VERSION ""

NS_ :

BS_:

BU_: VCU Orion_2_BMS Client TS_Fan_ECU TS_ECU5 TS_ECU4 TS_ECU3 TS_ECU2 TS_ECU1

BO_ 698 TS_ECU_ChargingStateTrigger: 1 Orion_2_BMS
 SG_ Orion_2_ChargePowerState : 0|1@1+ (1,0) [0|1] ""  TS_ECU5,TS_ECU4,TS_ECU3,TS_ECU2,TS_ECU1
 SG_ Orion_2_ChargeSafetyState : 1|1@1+ (1,0) [0|1] ""  TS_ECU5,TS_ECU4,TS_ECU3,TS_ECU2,TS_ECU1

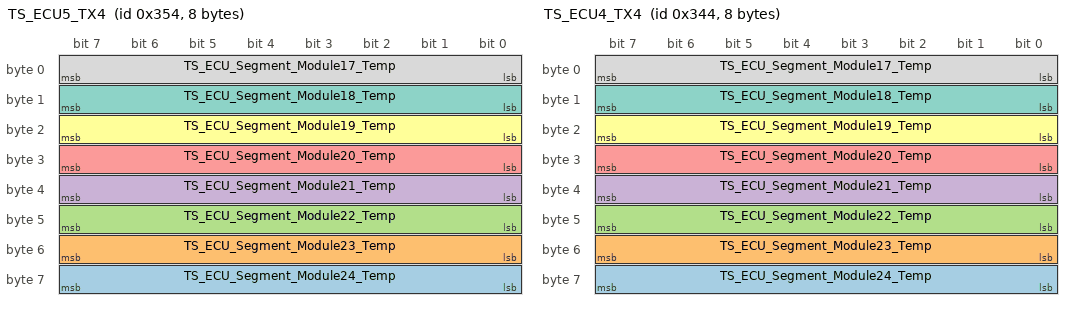
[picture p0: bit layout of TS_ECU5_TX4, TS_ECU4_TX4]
BO_ 852 TS_ECU5_TX4: 8 TS_ECU5
 SG_ TS_ECU_Segment_Module24_Temp : 63|8@0+ (1,-40) [-40|215] " °C"  Client
 SG_ TS_ECU_Segment_Module23_Temp : 48|8@1+ (1,-40) [-40|215] " °C"  Client
 SG_ TS_ECU_Segment_Module22_Temp : 40|8@1+ (1,-40) [-40|215] " °C"  Client
 SG_ TS_ECU_Segment_Module21_Temp : 32|8@1+ (1,-40) [-40|215] " °C"  Client
 SG_ TS_ECU_Segment_Module20_Temp : 24|8@1+ (1,-40) [-40|215] " °C"  Client
 SG_ TS_ECU_Segment_Module19_Temp : 16|8@1+ (1,-40) [-40|215] " °C"  Client
 SG_ TS_ECU_Segment_Module18_Temp : 8|8@1+ (1,-40) [-40|215] " °C"  Client
 SG_ TS_ECU_Segment_Module17_Temp : 0|8@1+ (1,-40) [-40|215] " °C"  Client

BO_ 836 TS_ECU4_TX4: 8 TS_ECU4
 SG_ TS_ECU_Segment_Module24_Temp : 63|8@0+ (1,-40) [-40|215] " °C"  Client
 SG_ TS_ECU_Segment_Module23_Temp : 48|8@1+ (1,-40) [-40|215] " °C"  Client
 SG_ TS_ECU_Segment_Module22_Temp : 40|8@1+ (1,-40) [-40|215] " °C"  Client
 SG_ TS_ECU_Segment_Module21_Temp : 32|8@1+ (1,-40) [-40|215] " °C"  Client
 SG_ TS_ECU_Segment_Module20_Temp : 24|8@1+ (1,-40) [-40|215] " °C"  Client
 SG_ TS_ECU_Segment_Module19_Temp : 16|8@1+ (1,-40) [-40|215] " °C"  Client
 SG_ TS_ECU_Segment_Module18_Temp : 8|8@1+ (1,-40) [-40|215] " °C"  Client
 SG_ TS_ECU_Segment_Module17_Temp : 0|8@1+ (1,-40) [-40|215] " °C"  Client

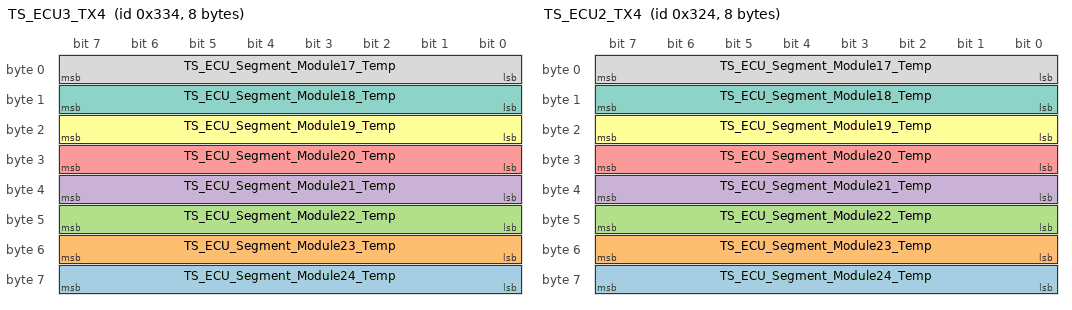
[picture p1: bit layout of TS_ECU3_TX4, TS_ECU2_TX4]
BO_ 820 TS_ECU3_TX4: 8 TS_ECU3
 SG_ TS_ECU_Segment_Module24_Temp : 63|8@0+ (1,-40) [-40|215] " °C"  Client
 SG_ TS_ECU_Segment_Module23_Temp : 48|8@1+ (1,-40) [-40|215] " °C"  Client
 SG_ TS_ECU_Segment_Module22_Temp : 40|8@1+ (1,-40) [-40|215] " °C"  Client
 SG_ TS_ECU_Segment_Module21_Temp : 32|8@1+ (1,-40) [-40|215] " °C"  Client
 SG_ TS_ECU_Segment_Module20_Temp : 24|8@1+ (1,-40) [-40|215] " °C"  Client
 SG_ TS_ECU_Segment_Module19_Temp : 16|8@1+ (1,-40) [-40|215] " °C"  Client
 SG_ TS_ECU_Segment_Module18_Temp : 8|8@1+ (1,-40) [-40|215] " °C"  Client
 SG_ TS_ECU_Segment_Module17_Temp : 0|8@1+ (1,-40) [-40|215] " °C"  Client

BO_ 804 TS_ECU2_TX4: 8 TS_ECU2
 SG_ TS_ECU_Segment_Module24_Temp : 63|8@0+ (1,-40) [-40|215] " °C"  Client
 SG_ TS_ECU_Segment_Module23_Temp : 48|8@1+ (1,-40) [-40|215] " °C"  Client
 SG_ TS_ECU_Segment_Module22_Temp : 40|8@1+ (1,-40) [-40|215] " °C"  Client
 SG_ TS_ECU_Segment_Module21_Temp : 32|8@1+ (1,-40) [-40|215] " °C"  Client
 SG_ TS_ECU_Segment_Module20_Temp : 24|8@1+ (1,-40) [-40|215] " °C"  Client
 SG_ TS_ECU_Segment_Module19_Temp : 16|8@1+ (1,-40) [-40|215] " °C"  Client
 SG_ TS_ECU_Segment_Module18_Temp : 8|8@1+ (1,-40) [-40|215] " °C"  Client
 SG_ TS_ECU_Segment_Module17_Temp : 0|8@1+ (1,-40) [-40|215] " °C"  Client

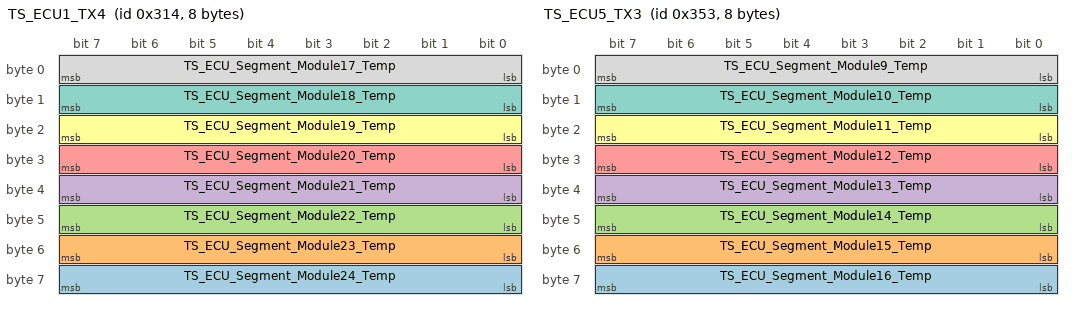
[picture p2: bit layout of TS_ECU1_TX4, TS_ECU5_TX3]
BO_ 788 TS_ECU1_TX4: 8 TS_ECU1
 SG_ TS_ECU_Segment_Module24_Temp : 63|8@0+ (1,-40) [-40|215] " °C"  Client
 SG_ TS_ECU_Segment_Module23_Temp : 48|8@1+ (1,-40) [-40|215] " °C"  Client
 SG_ TS_ECU_Segment_Module22_Temp : 40|8@1+ (1,-40) [-40|215] " °C"  Client
 SG_ TS_ECU_Segment_Module21_Temp : 32|8@1+ (1,-40) [-40|215] " °C"  Client
 SG_ TS_ECU_Segment_Module20_Temp : 24|8@1+ (1,-40) [-40|215] " °C"  Client
 SG_ TS_ECU_Segment_Module19_Temp : 16|8@1+ (1,-40) [-40|215] " °C"  Client
 SG_ TS_ECU_Segment_Module18_Temp : 8|8@1+ (1,-40) [-40|215] " °C"  Client
 SG_ TS_ECU_Segment_Module17_Temp : 0|8@1+ (1,-40) [-40|215] " °C"  Client

BO_ 851 TS_ECU5_TX3: 8 TS_ECU5
 SG_ TS_ECU_Segment_Module16_Temp : 56|8@1+ (1,-40) [-40|215] "°C"  Client
 SG_ TS_ECU_Segment_Module15_Temp : 48|8@1+ (1,-40) [-40|215] "°C"  Client
 SG_ TS_ECU_Segment_Module14_Temp : 40|8@1+ (1,-40) [-40|215] "°C"  Client
 SG_ TS_ECU_Segment_Module13_Temp : 32|8@1+ (1,-40) [-40|215] "°C"  Client
 SG_ TS_ECU_Segment_Module12_Temp : 24|8@1+ (1,-40) [-40|215] "°C"  Client
 SG_ TS_ECU_Segment_Module11_Temp : 16|8@1+ (1,0) [0|255] "°C"  Client
 SG_ TS_ECU_Segment_Module10_Temp : 8|8@1+ (1,-40) [-40|215] "°C"  Client
 SG_ TS_ECU_Segment_Module9_Temp : 0|8@1+ (1,-40) [-40|215] "°C"  Client

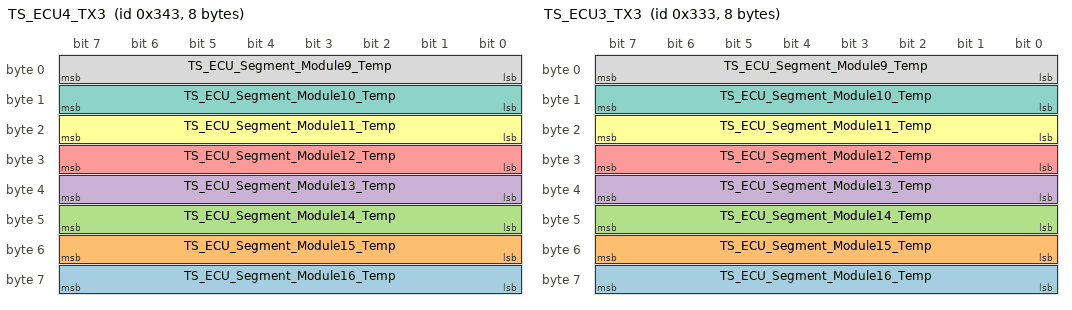
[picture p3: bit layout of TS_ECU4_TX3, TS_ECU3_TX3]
BO_ 835 TS_ECU4_TX3: 8 TS_ECU4
 SG_ TS_ECU_Segment_Module16_Temp : 56|8@1+ (1,-40) [-40|215] "°C"  Client
 SG_ TS_ECU_Segment_Module15_Temp : 48|8@1+ (1,-40) [-40|215] "°C"  Client
 SG_ TS_ECU_Segment_Module14_Temp : 40|8@1+ (1,-40) [-40|215] "°C"  Client
 SG_ TS_ECU_Segment_Module13_Temp : 32|8@1+ (1,-40) [-40|215] "°C"  Client
 SG_ TS_ECU_Segment_Module12_Temp : 24|8@1+ (1,-40) [-40|215] "°C"  Client
 SG_ TS_ECU_Segment_Module11_Temp : 16|8@1+ (1,0) [0|255] "°C"  Client
 SG_ TS_ECU_Segment_Module10_Temp : 8|8@1+ (1,-40) [-40|215] "°C"  Client
 SG_ TS_ECU_Segment_Module9_Temp : 0|8@1+ (1,-40) [-40|215] "°C"  Client

BO_ 819 TS_ECU3_TX3: 8 TS_ECU3
 SG_ TS_ECU_Segment_Module16_Temp : 56|8@1+ (1,-40) [-40|215] "°C"  Client
 SG_ TS_ECU_Segment_Module15_Temp : 48|8@1+ (1,-40) [-40|215] "°C"  Client
 SG_ TS_ECU_Segment_Module14_Temp : 40|8@1+ (1,-40) [-40|215] "°C"  Client
 SG_ TS_ECU_Segment_Module13_Temp : 32|8@1+ (1,-40) [-40|215] "°C"  Client
 SG_ TS_ECU_Segment_Module12_Temp : 24|8@1+ (1,-40) [-40|215] "°C"  Client
 SG_ TS_ECU_Segment_Module11_Temp : 16|8@1+ (1,0) [0|255] "°C"  Client
 SG_ TS_ECU_Segment_Module10_Temp : 8|8@1+ (1,-40) [-40|215] "°C"  Client
 SG_ TS_ECU_Segment_Module9_Temp : 0|8@1+ (1,-40) [-40|215] "°C"  Client

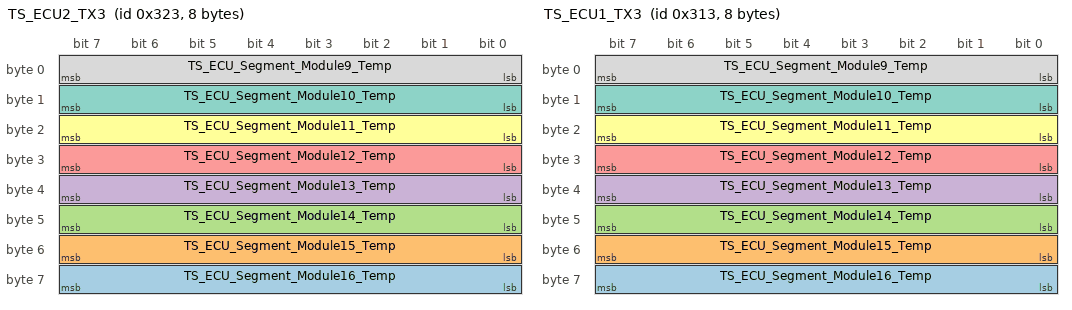
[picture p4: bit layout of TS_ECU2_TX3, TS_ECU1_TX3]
BO_ 803 TS_ECU2_TX3: 8 TS_ECU2
 SG_ TS_ECU_Segment_Module16_Temp : 56|8@1+ (1,-40) [-40|215] "°C"  Client
 SG_ TS_ECU_Segment_Module15_Temp : 48|8@1+ (1,-40) [-40|215] "°C"  Client
 SG_ TS_ECU_Segment_Module14_Temp : 40|8@1+ (1,-40) [-40|215] "°C"  Client
 SG_ TS_ECU_Segment_Module13_Temp : 32|8@1+ (1,-40) [-40|215] "°C"  Client
 SG_ TS_ECU_Segment_Module12_Temp : 24|8@1+ (1,-40) [-40|215] "°C"  Client
 SG_ TS_ECU_Segment_Module11_Temp : 16|8@1+ (1,0) [0|255] "°C"  Client
 SG_ TS_ECU_Segment_Module10_Temp : 8|8@1+ (1,-40) [-40|215] "°C"  Client
 SG_ TS_ECU_Segment_Module9_Temp : 0|8@1+ (1,-40) [-40|215] "°C"  Client

BO_ 787 TS_ECU1_TX3: 8 TS_ECU1
 SG_ TS_ECU_Segment_Module16_Temp : 56|8@1+ (1,-40) [-40|215] "°C"  Client
 SG_ TS_ECU_Segment_Module15_Temp : 48|8@1+ (1,-40) [-40|215] "°C"  Client
 SG_ TS_ECU_Segment_Module14_Temp : 40|8@1+ (1,-40) [-40|215] "°C"  Client
 SG_ TS_ECU_Segment_Module13_Temp : 32|8@1+ (1,-40) [-40|215] "°C"  Client
 SG_ TS_ECU_Segment_Module12_Temp : 24|8@1+ (1,-40) [-40|215] "°C"  Client
 SG_ TS_ECU_Segment_Module11_Temp : 16|8@1+ (1,0) [0|255] "°C"  Client
 SG_ TS_ECU_Segment_Module10_Temp : 8|8@1+ (1,-40) [-40|215] "°C"  Client
 SG_ TS_ECU_Segment_Module9_Temp : 0|8@1+ (1,-40) [-40|215] "°C"  Client

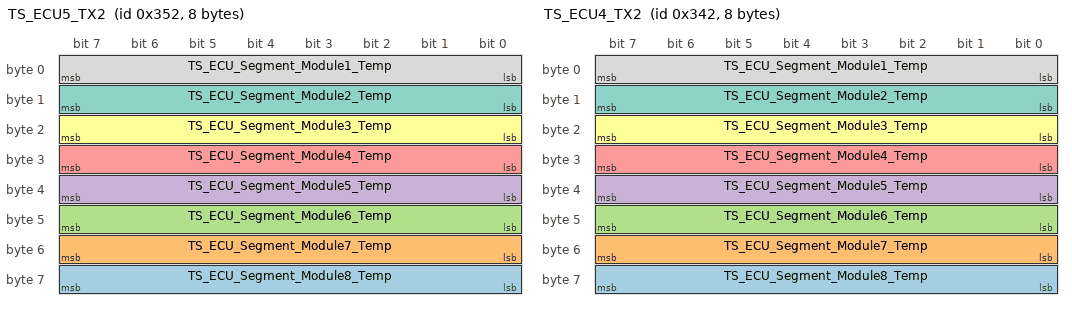
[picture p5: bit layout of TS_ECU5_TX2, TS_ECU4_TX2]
BO_ 850 TS_ECU5_TX2: 8 TS_ECU5
 SG_ TS_ECU_Segment_Module8_Temp : 56|8@1+ (1,-40) [-40|215] "°C"  Client
 SG_ TS_ECU_Segment_Module7_Temp : 48|8@1+ (1,-40) [-40|215] "°C"  Client
 SG_ TS_ECU_Segment_Module6_Temp : 40|8@1+ (1,-40) [-40|215] "°C"  Client
 SG_ TS_ECU_Segment_Module5_Temp : 32|8@1+ (1,-40) [-40|215] "°C"  Client
 SG_ TS_ECU_Segment_Module4_Temp : 24|8@1+ (1,-40) [-40|215] "°C"  Client
 SG_ TS_ECU_Segment_Module3_Temp : 16|8@1+ (1,-40) [-40|215] "°C"  Client
 SG_ TS_ECU_Segment_Module2_Temp : 8|8@1+ (1,-40) [-40|215] "°C"  Client
 SG_ TS_ECU_Segment_Module1_Temp : 0|8@1+ (1,-40) [-40|215] "°C"  Client

BO_ 834 TS_ECU4_TX2: 8 TS_ECU4
 SG_ TS_ECU_Segment_Module8_Temp : 56|8@1+ (1,-40) [-40|215] "°C"  Client
 SG_ TS_ECU_Segment_Module7_Temp : 48|8@1+ (1,-40) [-40|215] "°C"  Client
 SG_ TS_ECU_Segment_Module6_Temp : 40|8@1+ (1,-40) [-40|215] "°C"  Client
 SG_ TS_ECU_Segment_Module5_Temp : 32|8@1+ (1,-40) [-40|215] "°C"  Client
 SG_ TS_ECU_Segment_Module4_Temp : 24|8@1+ (1,-40) [-40|215] "°C"  Client
 SG_ TS_ECU_Segment_Module3_Temp : 16|8@1+ (1,-40) [-40|215] "°C"  Client
 SG_ TS_ECU_Segment_Module2_Temp : 8|8@1+ (1,-40) [-40|215] "°C"  Client
 SG_ TS_ECU_Segment_Module1_Temp : 0|8@1+ (1,-40) [-40|215] "°C"  Client

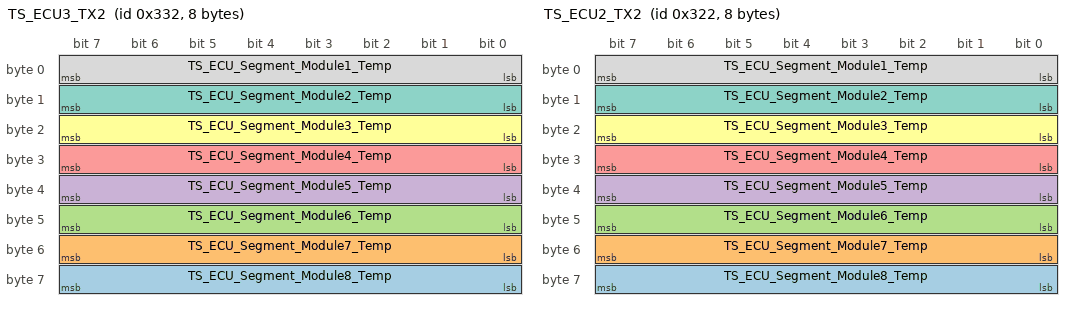
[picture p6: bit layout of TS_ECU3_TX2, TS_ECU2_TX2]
BO_ 818 TS_ECU3_TX2: 8 TS_ECU3
 SG_ TS_ECU_Segment_Module8_Temp : 56|8@1+ (1,-40) [-40|215] "°C"  Client
 SG_ TS_ECU_Segment_Module7_Temp : 48|8@1+ (1,-40) [-40|215] "°C"  Client
 SG_ TS_ECU_Segment_Module6_Temp : 40|8@1+ (1,-40) [-40|215] "°C"  Client
 SG_ TS_ECU_Segment_Module5_Temp : 32|8@1+ (1,-40) [-40|215] "°C"  Client
 SG_ TS_ECU_Segment_Module4_Temp : 24|8@1+ (1,-40) [-40|215] "°C"  Client
 SG_ TS_ECU_Segment_Module3_Temp : 16|8@1+ (1,-40) [-40|215] "°C"  Client
 SG_ TS_ECU_Segment_Module2_Temp : 8|8@1+ (1,-40) [-40|215] "°C"  Client
 SG_ TS_ECU_Segment_Module1_Temp : 0|8@1+ (1,-40) [-40|215] "°C"  Client

BO_ 802 TS_ECU2_TX2: 8 TS_ECU2
 SG_ TS_ECU_Segment_Module8_Temp : 56|8@1+ (1,-40) [-40|215] "°C"  Client
 SG_ TS_ECU_Segment_Module7_Temp : 48|8@1+ (1,-40) [-40|215] "°C"  Client
 SG_ TS_ECU_Segment_Module6_Temp : 40|8@1+ (1,-40) [-40|215] "°C"  Client
 SG_ TS_ECU_Segment_Module5_Temp : 32|8@1+ (1,-40) [-40|215] "°C"  Client
 SG_ TS_ECU_Segment_Module4_Temp : 24|8@1+ (1,-40) [-40|215] "°C"  Client
 SG_ TS_ECU_Segment_Module3_Temp : 16|8@1+ (1,-40) [-40|215] "°C"  Client
 SG_ TS_ECU_Segment_Module2_Temp : 8|8@1+ (1,-40) [-40|215] "°C"  Client
 SG_ TS_ECU_Segment_Module1_Temp : 0|8@1+ (1,-40) [-40|215] "°C"  Client

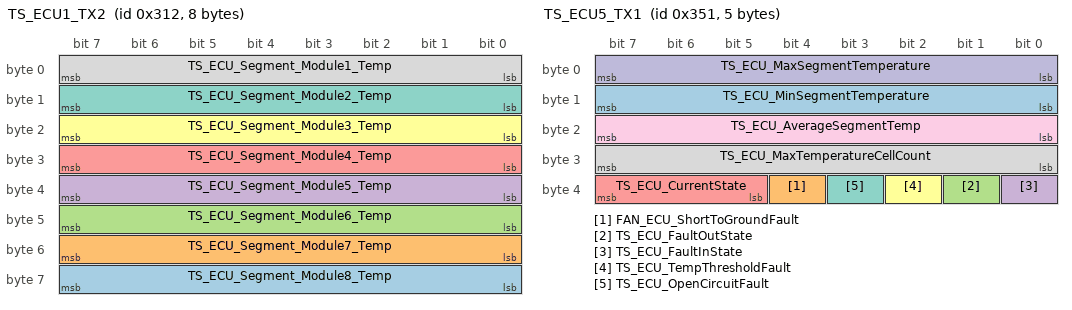
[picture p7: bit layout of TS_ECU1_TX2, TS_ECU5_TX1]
BO_ 786 TS_ECU1_TX2: 8 TS_ECU1
 SG_ TS_ECU_Segment_Module8_Temp : 56|8@1+ (1,-40) [-40|215] "°C"  Client
 SG_ TS_ECU_Segment_Module7_Temp : 48|8@1+ (1,-40) [-40|215] "°C"  Client
 SG_ TS_ECU_Segment_Module6_Temp : 40|8@1+ (1,-40) [-40|215] "°C"  Client
 SG_ TS_ECU_Segment_Module5_Temp : 32|8@1+ (1,-40) [-40|215] "°C"  Client
 SG_ TS_ECU_Segment_Module4_Temp : 24|8@1+ (1,-40) [-40|215] "°C"  Client
 SG_ TS_ECU_Segment_Module3_Temp : 16|8@1+ (1,-40) [-40|215] "°C"  Client
 SG_ TS_ECU_Segment_Module2_Temp : 8|8@1+ (1,-40) [-40|215] "°C"  Client
 SG_ TS_ECU_Segment_Module1_Temp : 0|8@1+ (1,-40) [-40|215] "°C"  Client

BO_ 770 TS_ECU_SYNC_RX2: 1 Client
 SG_ TS_ECU_SYNC_COUNTER : 0|8@1+ (1,0) [0|255] ""  TS_ECU1,TS_ECU5,TS_ECU4,TS_ECU3,TS_ECU2

BO_ 769 TS_ECU_SYNC_RX1: 1 TS_Fan_ECU
 SG_ TS_ECU_SYNC_COUNTER : 0|8@1+ (1,0) [0|255] ""  TS_ECU1,TS_ECU5,TS_ECU4,TS_ECU3,TS_ECU2

BO_ 849 TS_ECU5_TX1: 5 TS_ECU5
 SG_ TS_ECU_MinSegmentTemperature : 8|8@1+ (1,-40) [-40|215] "" Vector__XXX
 SG_ FAN_ECU_ShortToGroundFault : 36|1@1+ (1,0) [0|1] "" Vector__XXX
 SG_ TS_ECU_FaultOutState : 33|1@1+ (1,0) [0|1] "" Vector__XXX
 SG_ TS_ECU_FaultInState : 32|1@1+ (1,0) [0|1] "" Vector__XXX
 SG_ TS_ECU_CurrentState : 37|3@1+ (1,0) [0|1] "" Vector__XXX
 SG_ TS_ECU_TempThresholdFault : 34|1@1+ (1,0) [0|1] ""  VCU,TS_Fan_ECU,Client
 SG_ TS_ECU_OpenCircuitFault : 35|1@1+ (1,0) [0|1] ""  VCU,TS_Fan_ECU,Client
 SG_ TS_ECU_MaxTemperatureCellCount : 24|8@1+ (1,0) [0|63] ""  VCU,TS_Fan_ECU,Client
 SG_ TS_ECU_AverageSegmentTemp : 16|8@1+ (1,-40) [-40|215] " °C"  VCU,TS_Fan_ECU,Client
 SG_ TS_ECU_MaxSegmentTemperature : 0|8@1+ (1,-40) [-40|215] " °C"  VCU,TS_Fan_ECU,Client

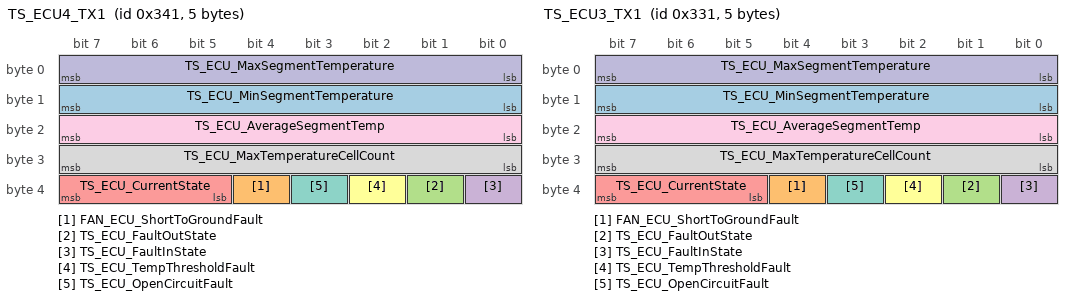
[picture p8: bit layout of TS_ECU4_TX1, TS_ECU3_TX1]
BO_ 833 TS_ECU4_TX1: 5 TS_ECU4
 SG_ TS_ECU_MinSegmentTemperature : 8|8@1+ (1,-40) [-40|215] "" Vector__XXX
 SG_ FAN_ECU_ShortToGroundFault : 36|1@1+ (1,0) [0|1] "" Vector__XXX
 SG_ TS_ECU_FaultOutState : 33|1@1+ (1,0) [0|1] "" Vector__XXX
 SG_ TS_ECU_FaultInState : 32|1@1+ (1,0) [0|1] "" Vector__XXX
 SG_ TS_ECU_CurrentState : 37|3@1+ (1,0) [0|1] "" Vector__XXX
 SG_ TS_ECU_TempThresholdFault : 34|1@1+ (1,0) [0|1] ""  VCU,TS_Fan_ECU,Client
 SG_ TS_ECU_OpenCircuitFault : 35|1@1+ (1,0) [0|1] ""  VCU,TS_Fan_ECU,Client
 SG_ TS_ECU_MaxTemperatureCellCount : 24|8@1+ (1,0) [0|63] ""  VCU,TS_Fan_ECU,Client
 SG_ TS_ECU_AverageSegmentTemp : 16|8@1+ (1,-40) [-40|215] " °C"  VCU,TS_Fan_ECU,Client
 SG_ TS_ECU_MaxSegmentTemperature : 0|8@1+ (1,-40) [-40|215] " °C"  VCU,TS_Fan_ECU,Client

BO_ 817 TS_ECU3_TX1: 5 TS_ECU3
 SG_ TS_ECU_MinSegmentTemperature : 8|8@1+ (1,-40) [-40|215] "" Vector__XXX
 SG_ FAN_ECU_ShortToGroundFault : 36|1@1+ (1,0) [0|1] "" Vector__XXX
 SG_ TS_ECU_FaultOutState : 33|1@1+ (1,0) [0|1] "" Vector__XXX
 SG_ TS_ECU_FaultInState : 32|1@1+ (1,0) [0|1] "" Vector__XXX
 SG_ TS_ECU_CurrentState : 37|3@1+ (1,0) [0|1] "" Vector__XXX
 SG_ TS_ECU_TempThresholdFault : 34|1@1+ (1,0) [0|1] ""  VCU,TS_Fan_ECU,Client
 SG_ TS_ECU_OpenCircuitFault : 35|1@1+ (1,0) [0|1] ""  VCU,TS_Fan_ECU,Client
 SG_ TS_ECU_MaxTemperatureCellCount : 24|8@1+ (1,0) [0|63] ""  VCU,TS_Fan_ECU,Client
 SG_ TS_ECU_AverageSegmentTemp : 16|8@1+ (1,-40) [-40|215] " °C"  VCU,TS_Fan_ECU,Client
 SG_ TS_ECU_MaxSegmentTemperature : 0|8@1+ (1,-40) [-40|215] " °C"  VCU,TS_Fan_ECU,Client

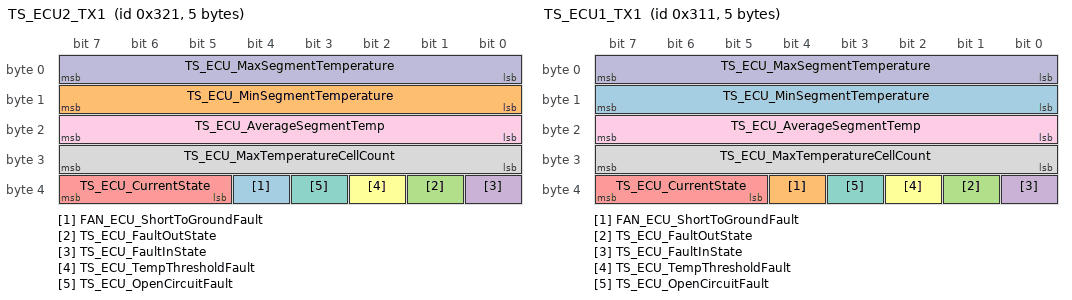
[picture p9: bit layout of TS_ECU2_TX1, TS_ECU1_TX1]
BO_ 801 TS_ECU2_TX1: 5 TS_ECU2
 SG_ FAN_ECU_ShortToGroundFault : 36|1@1+ (1,0) [0|1] "" Vector__XXX
 SG_ TS_ECU_MinSegmentTemperature : 8|8@1+ (1,-40) [-40|215] "" Vector__XXX
 SG_ TS_ECU_FaultOutState : 33|1@1+ (1,0) [0|1] "" Vector__XXX
 SG_ TS_ECU_FaultInState : 32|1@1+ (1,0) [0|1] "" Vector__XXX
 SG_ TS_ECU_CurrentState : 37|3@1+ (1,0) [0|1] "" Vector__XXX
 SG_ TS_ECU_TempThresholdFault : 34|1@1+ (1,0) [0|1] ""  VCU,TS_Fan_ECU,Client
 SG_ TS_ECU_OpenCircuitFault : 35|1@1+ (1,0) [0|1] ""  VCU,TS_Fan_ECU,Client
 SG_ TS_ECU_MaxTemperatureCellCount : 24|8@1+ (1,0) [0|63] ""  VCU,TS_Fan_ECU,Client
 SG_ TS_ECU_AverageSegmentTemp : 16|8@1+ (1,-40) [-40|215] " °C"  VCU,TS_Fan_ECU,Client
 SG_ TS_ECU_MaxSegmentTemperature : 0|8@1+ (1,-40) [-40|215] " °C"  VCU,TS_Fan_ECU,Client

BO_ 785 TS_ECU1_TX1: 5 TS_ECU1
 SG_ TS_ECU_MinSegmentTemperature : 8|8@1+ (1,-40) [-40|215] "" Vector__XXX
 SG_ FAN_ECU_ShortToGroundFault : 36|1@1+ (1,0) [0|1] "" Vector__XXX
 SG_ TS_ECU_FaultOutState : 33|1@1+ (1,0) [0|1] "" Vector__XXX
 SG_ TS_ECU_FaultInState : 32|1@1+ (1,0) [0|1] "" Vector__XXX
 SG_ TS_ECU_CurrentState : 37|3@1+ (1,0) [0|1] "" Vector__XXX
 SG_ TS_ECU_TempThresholdFault : 34|1@1+ (1,0) [0|1] ""  VCU,TS_Fan_ECU,Client
 SG_ TS_ECU_OpenCircuitFault : 35|1@1+ (1,0) [0|1] ""  VCU,TS_Fan_ECU,Client
 SG_ TS_ECU_MaxTemperatureCellCount : 24|8@1+ (1,0) [0|63] ""  VCU,Client,TS_Fan_ECU
 SG_ TS_ECU_AverageSegmentTemp : 16|8@1+ (1,-40) [-40|215] " °C"  VCU,Client,TS_Fan_ECU
 SG_ TS_ECU_MaxSegmentTemperature : 0|8@1+ (1,-40) [-40|215] " °C"  VCU,Client,TS_Fan_ECU

BO_TX_BU_ 769 : VCU,Client,TS_Fan_ECU;

CM_ BU_ Client "Client can be:
1) Vehicle Control Unit (VCU)
2) Can Adapter
";
BA_DEF_  "BusType" STRING ;
BA_DEF_DEF_  "BusType" "CAN";
